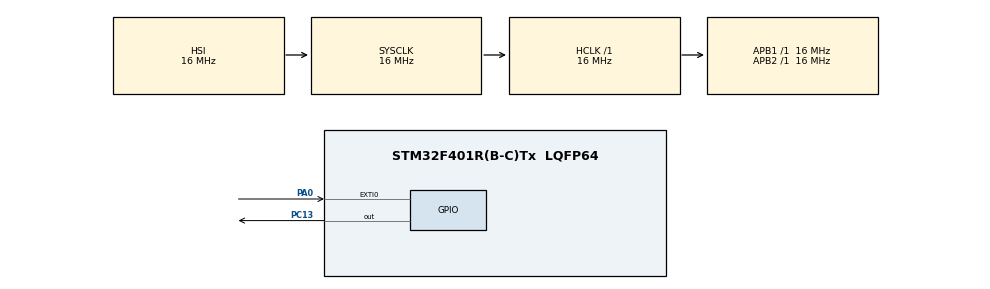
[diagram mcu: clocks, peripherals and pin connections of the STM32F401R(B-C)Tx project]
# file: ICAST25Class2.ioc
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Mcu.Family=STM32F4
Mcu.Name=STM32F401R(B-C)Tx
Mcu.Package=LQFP64
NVIC.EXTI0_IRQn=true\:0\:0\:false\:false\:true\:true\:true\:true
NVIC.PriorityGroup=NVIC_PRIORITYGROUP_4
PA0-WKUP.GPIO_ModeDefaultEXTI=GPIO_MODE_IT_FALLING
PA0-WKUP.GPIO_PuPd=GPIO_PULLUP
PA0-WKUP.Signal=GPXTI0
PA13.Mode=Serial_Wire
PA13.Signal=SYS_JTMS-SWDIO
PA14.Mode=Serial_Wire
PA14.Signal=SYS_JTCK-SWCLK
PC13-ANTI_TAMP.GPIO_ModeDefaultOutputPP=GPIO_MODE_OUTPUT_PP
PC13-ANTI_TAMP.GPIO_PuPd=GPIO_PULLDOWN
PC13-ANTI_TAMP.Signal=GPIO_Output
ProjectManager.HeapSize=0x200
ProjectManager.StackSize=0x400
ProjectManager.TargetToolchain=MDK-ARM V5.32
RCC.AHBFreq_Value=16000000
RCC.APB1Freq_Value=16000000
RCC.APB2Freq_Value=16000000
RCC.CortexFreq_Value=16000000
RCC.HSE_VALUE=25000000
RCC.HSI_VALUE=16000000
RCC.LSE_VALUE=32768
RCC.SYSCLKFreq_VALUE=16000000
RCC.VCOOutputFreq_Value=192000000
board=custom

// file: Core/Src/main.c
/* USER CODE BEGIN Header */
/**
  ******************************************************************************
  * @file           : main.c
  * @brief          : Main program body
  ******************************************************************************
  * @attention
  *
  * Copyright (c) 2025 STMicroelectronics.
  * All rights reserved.
  *
  * This software is licensed under terms that can be found in the LICENSE file
  * in the root directory of this software component.
  * If no LICENSE file comes with this software, it is provided AS-IS.
  *
  ******************************************************************************
  */
/* USER CODE END Header */
#include "main.h"
#include "gpio.h"

/* USER CODE BEGIN Includes */
#include <stdint.h>
/* USER CODE END Includes */

/* USER CODE BEGIN PV */
volatile int key;
uint32_t key_prev, key_cur;
/* USER CODE END PV */

void SystemClock_Config(void);

int main(void)
{

  /* MCU Configuration--------------------------------------------------------*/

  /* Reset of all peripherals, Initializes the Flash interface and the Systick. */
  HAL_Init();

  /* Configure the system clock */
  SystemClock_Config();

  /* Initialize all configured peripherals */
  MX_GPIO_Init();
  /* USER CODE BEGIN 2 */

	key = 0;

  /* USER CODE END 2 */

  /* Infinite loop */
  /* USER CODE BEGIN WHILE */
  while (1)
  {
		if (key > 0) {
			key_cur = HAL_GetTick();
			if (key_cur - key_prev > 20) {
				key_prev = key_cur;
				if (HAL_GPIO_ReadPin(GPIOA, GPIO_PIN_0)) {
					key = -1 - (key > 50);
				}
				else {
					key++;
				}
			}
		}
		else if (key < 0) {
			switch (key) {
				case -2:
					HAL_GPIO_TogglePin(GPIOC, GPIO_PIN_13);
					HAL_Delay(500);
				case -1:
					HAL_GPIO_TogglePin(GPIOC, GPIO_PIN_13);
					key = -3;
					break;
				default:
					if (HAL_GetTick() - key_prev > 20) {
							key = 0;
							// EXTI->IMR |= 0x01;
							HAL_NVIC_EnableIRQ(EXTI0_IRQn);
					}
					break;
			}
		}
    /* USER CODE END WHILE */

  }
}

void SystemClock_Config(void)
{
  RCC_OscInitTypeDef RCC_OscInitStruct = {0};
  RCC_ClkInitTypeDef RCC_ClkInitStruct = {0};

  /** Configure the main internal regulator output voltage
  */
  __HAL_RCC_PWR_CLK_ENABLE();
  __HAL_PWR_VOLTAGESCALING_CONFIG(PWR_REGULATOR_VOLTAGE_SCALE2);

  /** Initializes the RCC Oscillators according to the specified parameters
  * in the RCC_OscInitTypeDef structure.
  */
  RCC_OscInitStruct.OscillatorType = RCC_OSCILLATORTYPE_HSI;
  RCC_OscInitStruct.HSIState = RCC_HSI_ON;
  RCC_OscInitStruct.HSICalibrationValue = RCC_HSICALIBRATION_DEFAULT;
  RCC_OscInitStruct.PLL.PLLState = RCC_PLL_NONE;
  if (HAL_RCC_OscConfig(&RCC_OscInitStruct) != HAL_OK)
  {
    Error_Handler();
  }

  /** Initializes the CPU, AHB and APB buses clocks
  */
  RCC_ClkInitStruct.ClockType = RCC_CLOCKTYPE_HCLK|RCC_CLOCKTYPE_SYSCLK
                              |RCC_CLOCKTYPE_PCLK1|RCC_CLOCKTYPE_PCLK2;
  RCC_ClkInitStruct.SYSCLKSource = RCC_SYSCLKSOURCE_HSI;
  RCC_ClkInitStruct.AHBCLKDivider = RCC_SYSCLK_DIV1;
  RCC_ClkInitStruct.APB1CLKDivider = RCC_HCLK_DIV1;
  RCC_ClkInitStruct.APB2CLKDivider = RCC_HCLK_DIV1;

  if (HAL_RCC_ClockConfig(&RCC_ClkInitStruct, FLASH_LATENCY_0) != HAL_OK)
  {
    Error_Handler();
  }
}

void Error_Handler(void)
{
  __disable_irq();
  while (1)
  {
  }
}
